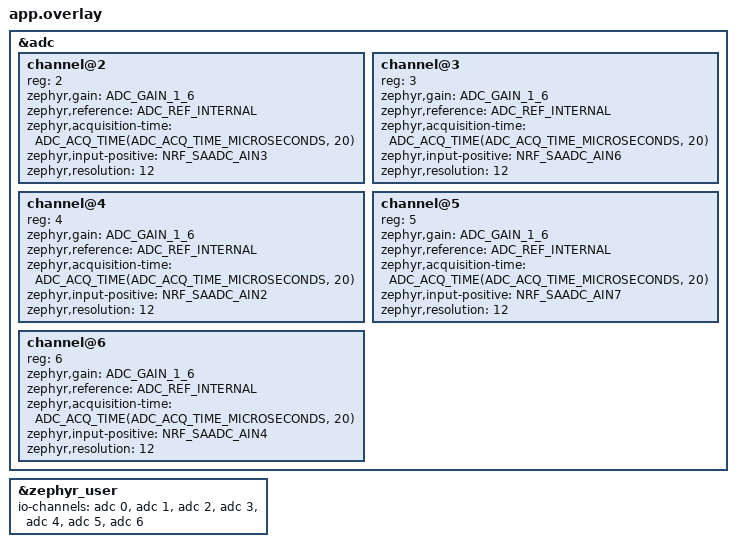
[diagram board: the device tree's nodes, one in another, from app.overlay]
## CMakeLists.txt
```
cmake_minimum_required(VERSION 3.20.0)
find_package(Zephyr REQUIRED HINTS $ENV{ZEPHYR_BASE})
project(sp1-looper)
include(${ZEPHYR_BASE}/samples/subsys/usb/common/common.cmake)
target_sources(app PRIVATE src/main.c src/sp1_emmc.c)

# -fno-strict-aliasing: the firmware type-puns static uint8_t[] storage through
# int16_t* / struct* lvalues (the batchbuf copies and the meta-block cast). This
# removes the TBAA assumption so those puns stay correct under -O2 -- the same
# idiom the Linux kernel and Zephyr core build with. Purely subtractive; it can
# only remove an optimizer assumption, never miscompile correct code.
target_compile_options(app PRIVATE -fno-strict-aliasing)

# NOTE: -O2 on sp1_emmc.c was REVERTED. It sped up reads but BROKE the timing-
# sensitive flash WRITE bit-bang -- ~half of writes failed CRC and retried, which
# overflowed the record ring under record+play load (corruption/glitching). The
# eMMC driver stays at the global -Os, where the write timing is correct.

target_sources_ifdef(CONFIG_SP1_BT_ID_PROBE app PRIVATE src/sp1_bt_probe.c)

# Integration296: maintained source-tree runtime; no build-time source swapping.
set(SP1_BT_DIR ${CMAKE_CURRENT_SOURCE_DIR}/bt)
target_sources(app PRIVATE ${SP1_BT_DIR}/runtime/usb_midi.c)
file(GLOB SP1_SBC_SOURCES ${SP1_BT_DIR}/audio-pipeline/decoder/srce/*.c)
list(FILTER SP1_SBC_SOURCES EXCLUDE REGEX "(synthesis-dct8|decoder-private|synthesis-8-generated).c$")
target_sources(app PRIVATE ${SP1_BT_DIR}/runtime/synthesis-dct8.c ${SP1_BT_DIR}/runtime/decoder-private.c ${SP1_BT_DIR}/runtime/synthesis-8-generated.c ${SP1_SBC_SOURCES} ${SP1_BT_DIR}/runtime/audio_decode.c)
target_include_directories(app PRIVATE ${SP1_BT_DIR}/runtime ${SP1_BT_DIR}/audio-pipeline ${SP1_BT_DIR}/audio-pipeline/decoder/include ${SP1_BT_DIR}/audio-pipeline/decoder/srce)
set_source_files_properties(${SP1_SBC_SOURCES} ${SP1_BT_DIR}/runtime/synthesis-dct8.c ${SP1_BT_DIR}/runtime/decoder-private.c ${SP1_BT_DIR}/runtime/synthesis-8-generated.c PROPERTIES COMPILE_OPTIONS "-fwrapv")
# Candidate344: optimize only SBC decoding and its PCM mix wrapper for speed.
# Keep signed-wrap semantics for codec arithmetic. Never change timing-sensitive
# eMMC/USB/control compilation as a side effect of this experiment.
set_property(SOURCE ${SP1_SBC_SOURCES} ${SP1_BT_DIR}/runtime/synthesis-dct8.c ${SP1_BT_DIR}/runtime/decoder-private.c ${SP1_BT_DIR}/runtime/synthesis-8-generated.c ${SP1_BT_DIR}/runtime/audio_decode.c APPEND PROPERTY COMPILE_OPTIONS -O2)
get_target_property(SP1_CDC_SOURCES subsys__usb__device_next SOURCES)
list(FILTER SP1_CDC_SOURCES EXCLUDE REGEX "usbd_cdc_acm.c$")
set_property(TARGET subsys__usb__device_next PROPERTY SOURCES ${SP1_CDC_SOURCES})
target_sources(subsys__usb__device_next PRIVATE ${SP1_BT_DIR}/runtime/usbd_cdc_acm.c)
target_compile_options(app PRIVATE -fstack-usage)

target_sources(app PRIVATE src/storage373.c)

target_compile_definitions(app PRIVATE FS_FATFS_WINDOW_ALIGNMENT=4)
target_sources(app PRIVATE src/ff.c src/pool.c src/take.c src/session.c src/control.c src/edit.c src/runtime.c src/store_core.c src/admit.c src/backend.c src/audit.c)

target_sources(app PRIVATE src/handoff.c)

target_sources(app PRIVATE src/geometry.c)

target_sources(app PRIVATE src/engine.c src/controls.c src/snapshot.c)

target_sources(app PRIVATE src/cooperative.c)

# Pin414 USB class error-payload fix locally; do not alter the shared SDK.
get_target_property(SP1_UAC_SOURCES subsys__usb__device_next SOURCES)
list(FILTER SP1_UAC_SOURCES EXCLUDE REGEX "usbd_uac2.c$")
set_property(TARGET subsys__usb__device_next PROPERTY SOURCES ${SP1_UAC_SOURCES})
target_sources(subsys__usb__device_next PRIVATE ${SP1_BT_DIR}/runtime/usbd_uac2.c)

# Paged capacity candidate: all metadata buffers overlay the existing batch.
target_sources(app PRIVATE src/paged_bridge.c ../paged/store.c ../paged/catalog.c ../paged/allocate.c ../paged/io.c ../paged/music.c ../paged/session.c ../paged/preview.c)

set(SP1_CAPACITY_BUILD 422 CACHE STRING "Capacity diagnostic identity")
target_compile_definitions(app PRIVATE SP1_CAPACITY_BUILD=${SP1_CAPACITY_BUILD})
```

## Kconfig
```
# SP-1 marisko firmware application Kconfig.
#
# Pulls in the common USB sample options (CONFIG_SAMPLE_USBD_VID/PID/PRODUCT/...)
# consumed by the vendored sample_usbd_init.c device_next bring-up helper, then
# the standard Zephyr Kconfig tree.

source "samples/subsys/usb/common/Kconfig.sample_usbd"

config SP1_BT_ID_PROBE
	bool "Experimental one-shot radio identity probe"
	default n

config SP1_LINK_CALIBRATION
	bool "Stopped-device linked audio calibration experiment"
	depends on SP1_BT_ID_PROBE
	default n

source "Kconfig.zephyr"
```

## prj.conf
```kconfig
CONFIG_PM=y
CONFIG_PM_DEVICE=n
CONFIG_LOG=n
CONFIG_ASSERT=n
CONFIG_USE_SEGGER_RTT=n
CONFIG_IDLE_STACK_SIZE=128
CONFIG_ISR_STACK_SIZE=512
CONFIG_WATCHDOG=y

# ---- FAILSAFES: catch stack overflow / bad memory access cleanly (MPU guard +
# stack canary). Any fatal fault is turned into a reboot by k_sys_fatal_error_handler
# in main.c, and the 4 s watchdog is the final backstop for a hang. ----
# HK-613 (audit §2.5): the MPU stack guard is reprogrammed on every context
# switch (~1 % at the corner). Off; the STACK_SENTINEL canary below, which
# Kconfig had been silently excluding (depends on !MPU_STACK_GUARD), now
# takes effect -- overflow is caught at the next switch/ISR exit, not never.
CONFIG_HW_STACK_PROTECTION=n
CONFIG_STACK_SENTINEL=y
CONFIG_REBOOT=y
CONFIG_CLOCK_CONTROL=y
CONFIG_CLOCK_CONTROL_NRF_K32SRC_SYNTH=y

# ---- USB-serial diagnostics console (CDC ACM) ----
CONFIG_PRINTK=y
CONFIG_SERIAL=y
CONFIG_CONSOLE=y
CONFIG_UART_CONSOLE=y
CONFIG_UART_LINE_CTRL=y
CONFIG_UART_INTERRUPT_DRIVEN=y

# ---- Milestone 3: USB-C audio IN (UAC2) on the new device_next USB stack ----
# UAC2 only exists on the new stack, which is mutually exclusive with the legacy
# CONFIG_USB_DEVICE_STACK. The CDC console therefore moves to device_next too and
# enumerates as a composite (UAC2 speaker + CDC ACM) device.
CONFIG_USB_DEVICE_STACK_NEXT=y
CONFIG_USBD_AUDIO2_CLASS=y
CONFIG_USBD_CDC_ACM_CLASS=y
# SOF events drive the explicit-feedback regulator (sof_cb / feedback_cb).
CONFIG_UDC_ENABLE_SOF=n
# The app owns the single composite USBD context; do NOT let the CDC SYS_INIT
# build a second private context that would fight for the controller.
CONFIG_CDC_ACM_SERIAL_INITIALIZE_AT_BOOT=n
# Serial-number string descriptor.
CONFIG_HWINFO=y
# Composite device identity (replaces the legacy VID/PID/strings). New PID so a
# host does not reuse a cached CDC-only driver from the old firmware.
CONFIG_SAMPLE_USBD_VID=0x1915
CONFIG_SAMPLE_USBD_PID=0x5210
CONFIG_SAMPLE_USBD_MANUFACTURER="softmodded"
CONFIG_SAMPLE_USBD_PRODUCT="SP-1 Audio"
# WINDOWS: usbaudio2.sys demands a 4-byte Full-Speed feedback endpoint (the
# USB spec says 3) and a Q16.16 value — without this the device enumerates
# with a yellow triangle / Code 10 ("cannot start") on Windows. Linux and
# macOS parse the format from the declared size, so this is host-universal.
# (Backported into the Zephyr tree; upstream: USBD_UAC2_FS_WINDOWS_WORKAROUND,
# zephyrproject-rtos/zephyr issue #77212.)
CONFIG_USBD_UAC2_FS_WINDOWS_WORKAROUND=y
# HK-613 (audit §2.5): per-thread cycle accounting cost ~0.5 % per switch and
# only fed the CPU= line; the W4Y census has been the instrument since 473.
CONFIG_THREAD_RUNTIME_STATS=n
CONFIG_SCHED_THREAD_USAGE=n
# iOS: iPhones/iPads reject accessories claiming more than 100 mA over the
# camera adapter. The SP-1 runs from its own battery and barely sips the bus,
# so claim 100 mA (units of 2 mA) instead of the 250 mA default.
CONFIG_SAMPLE_USBD_MAX_POWER=50

# ---- ADC for the button ladders / faders ----
CONFIG_ADC=y

# ---- Milestone 2: I2C to the audio codecs (CS42L42 / TAS2505) ----
CONFIG_I2C=y

# ---- Milestone 2b: I2S audio out (nRF master) ----
CONFIG_I2S=y
CONFIG_I2S_NRFX=y
CONFIG_FPU=y
# NOTE: deliberately NOT setting CONFIG_SPEED_OPTIMIZATIONS=y (-O2). It crashed the
# device on hardware -- this ae5b2e8-derived code has latent signed-overflow UB in
# the mixer interp that -O2 weaponizes. Default -Os is stable. Re-enabling -O2 would
# require fixing that UB (int64 interp) FIRST. Stay on -Os.

# USB stack + printf need a roomier main stack than the bare power build;
# device_next USBD init (descriptor build + class registration) wants headroom.
CONFIG_MAIN_STACK_SIZE=2048

# ---- Always-dim LEDs (fork): the soft-PWM LED timer ISR runs as a ZERO-
# LATENCY interrupt so kernel locks / other IRQs can't delay its on/off edges
# (edge jitter at low duty = visible flicker). The ISR is pure register IO. ----
CONFIG_ZERO_LATENCY_IRQS=y

# SS-473 (probe only -- reverted with prj.conf on exit)
CONFIG_INIT_STACKS=y
CONFIG_THREAD_STACK_INFO=y

CONFIG_COMMON_LIBC_MALLOC_ARENA_SIZE=0
```

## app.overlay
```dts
#include <zephyr/dt-bindings/adc/adc.h>
#include <zephyr/dt-bindings/adc/nrf-saadc.h>
#include <zephyr/dt-bindings/pinctrl/nrf-pinctrl.h>

/* NO MIDI UART: the SP-1 has no MIDI jack. P1.04 (the earlier best-guess MIDI
 * pin) is actually the CYBT-353027 Bluetooth module's UART line per TimK's
 * stemplayer_pins.h — driving it risked contention with the module. The TE
 * firmware's MIDI sync rides the 3.5 mm TRS jack by a path not in the published
 * pinout; revisit only with hardware tracing. */

&adc {
	channel@2 { reg = <2>; zephyr,gain = "ADC_GAIN_1_6"; zephyr,reference = "ADC_REF_INTERNAL";
		zephyr,acquisition-time = <ADC_ACQ_TIME(ADC_ACQ_TIME_MICROSECONDS, 20)>;
		zephyr,input-positive = <NRF_SAADC_AIN3>; zephyr,resolution = <12>; };   /* Fader 1 P0.05 */
	channel@3 { reg = <3>; zephyr,gain = "ADC_GAIN_1_6"; zephyr,reference = "ADC_REF_INTERNAL";
		zephyr,acquisition-time = <ADC_ACQ_TIME(ADC_ACQ_TIME_MICROSECONDS, 20)>;
		zephyr,input-positive = <NRF_SAADC_AIN6>; zephyr,resolution = <12>; };   /* Fader 2 P0.30 */
	channel@4 { reg = <4>; zephyr,gain = "ADC_GAIN_1_6"; zephyr,reference = "ADC_REF_INTERNAL";
		zephyr,acquisition-time = <ADC_ACQ_TIME(ADC_ACQ_TIME_MICROSECONDS, 20)>;
		zephyr,input-positive = <NRF_SAADC_AIN2>; zephyr,resolution = <12>; };   /* Fader 3 P0.04 */
	channel@5 { reg = <5>; zephyr,gain = "ADC_GAIN_1_6"; zephyr,reference = "ADC_REF_INTERNAL";
		zephyr,acquisition-time = <ADC_ACQ_TIME(ADC_ACQ_TIME_MICROSECONDS, 20)>;
		zephyr,input-positive = <NRF_SAADC_AIN7>; zephyr,resolution = <12>; };   /* Fader 4 P0.31 */
	channel@6 { reg = <6>; zephyr,gain = "ADC_GAIN_1_6"; zephyr,reference = "ADC_REF_INTERNAL";
		zephyr,acquisition-time = <ADC_ACQ_TIME(ADC_ACQ_TIME_MICROSECONDS, 20)>;
		zephyr,input-positive = <NRF_SAADC_AIN4>; zephyr,resolution = <12>; };   /* Battery level P0.28 (divider, per SP-1-dev wiki) */
};
&zephyr_user {
	io-channels = <&adc 0>, <&adc 1>, <&adc 2>, <&adc 3>, <&adc 4>, <&adc 5>, <&adc 6>;
};
```

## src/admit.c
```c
#include "admit.h"
#include "store_core.h"
#include <string.h>
typedef struct {FATFS *fs;pool_io io;uint8_t *scratch;uint32_t cached;bool have_cache;} fat_reader;
static uint32_t get32(const uint8_t *p){return p[0]|(uint32_t)p[1]<<8|(uint32_t)p[2]<<16|(uint32_t)p[3]<<24;}
static bool entry(void *ctx,uint32_t cluster,uint32_t *value){
 fat_reader *r=ctx;uint32_t sector=cluster/128,offset=(cluster%128)*4;
 if(cluster>=r->fs->n_fatent||sector>=r->fs->fsize)return false;
 uint64_t a=(uint64_t)r->fs->fatbase+sector,b=a+r->fs->fsize;
 if(b>=r->io.device_blocks)return false;
 if(!r->have_cache||r->cached!=sector){
  if(!r->io.read(r->io.context,(uint32_t)a,r->scratch,1)||
     !r->io.read(r->io.context,(uint32_t)b,r->scratch+512,1))return false;
  r->cached=sector;r->have_cache=true;
 }
 uint32_t first=get32(r->scratch+offset)&0x0fffffff;
 if(first!=(get32(r->scratch+512+offset)&0x0fffffff))return false;
 *value=first;return true;
}
static bool admit(FATFS *fs,pool_io raw,pool_io *out,uint8_t scratch[1024],FIL *file,bool paged){
 if(!fs||!out||!scratch||!file||!raw.read||!raw.write||!raw.sync||fs->fs_type!=FS_FAT32||
    fs->n_fats!=2||fs->n_fatent<65527||!fs->csize||fs->csize>128||
    (fs->csize&(fs->csize-1))||fs->database>=raw.device_blocks)return false;
 uint64_t data_blocks=(uint64_t)(fs->n_fatent-2)*fs->csize;
 if(data_blocks>raw.device_blocks-fs->database)return false;
 sp1_volume data={raw.device_blocks,(uint32_t)fs->database,(uint32_t)data_blocks};
 fat_reader reader={.fs=fs,.io=raw,.scratch=scratch};sp1_extent e[3];
 /* Resolve once during admission, never in the audio/refill path. A present but
  * damaged new namespace must not silently fall back to an old library. */
 const char *names[]={"TAPELOOP/CAT0.BIN","TAPELOOP/CAT1.BIN","TAPELOOP/AUDIO.BIN"};
 FILINFO namespace_info;
 FRESULT ns=f_stat("TAPELOOP",&namespace_info);
 if(ns==FR_NO_FILE||ns==FR_NO_PATH){names[0]="SP1/CAT0.BIN";names[1]="SP1/CAT1.BIN";names[2]="SP1/AUDIO.BIN";}
 else if(ns!=FR_OK||!(namespace_info.fattrib&AM_DIR))return false;
 if(paged){
  if(ns!=FR_OK)return false;
  for(unsigned i=0;i<2;i++){FRESULT old=f_stat(names[i],&namespace_info);if(old!=FR_NO_FILE&&old!=FR_NO_PATH)return false;}
  names[0]="TAPELOOP/INDEX0.BIN";names[1]="TAPELOOP/INDEX1.BIN";
 }
 for(unsigned i=0;i<3;i++){
  if(f_open(file,names[i],FA_READ)!=FR_OK)return false;
  uint64_t bytes=f_size(file);uint32_t cluster=file->obj.sclust;
  bool valid=file->obj.fs==fs&&bytes&&bytes%512==0&&bytes/512<=UINT32_MAX&&
             (i==2?bytes>=16384:bytes==(paged?4194304u:4096u));
  if(f_close(file)!=FR_OK||!valid)return false;
  uint32_t blocks=(uint32_t)(bytes/512),clusters=(blocks+fs->csize-1)/fs->csize;
  if(!sp1_fat_contiguous(data,fs->csize,fs->n_fatent-2,cluster,clusters,entry,&reader,&e[i]))return false;
  /* Catalog files may occupy larger clusters, but the audio pool must consume
   * its whole reservation so allocation cannot expose FAT file slack. */
  if(i==2&&e[i].count!=blocks)return false;
 }
 if(!sp1_extents_disjoint(data,e,3))return false;
 raw.catalog[0]=e[0].first;raw.catalog[1]=e[1].first;raw.pool_first=e[2].first;raw.pool_blocks=e[2].count;
 *out=raw;return true;
}

bool music_fat_admit(FATFS *fs,pool_io raw,pool_io *out,uint8_t scratch[1024]){
 FIL file;return music_fat_admit_workspace(fs,raw,out,scratch,&file);
}

bool music_fat_admit_workspace(FATFS*f,pool_io r,pool_io*out,uint8_t s[1024],FIL*file){return admit(f,r,out,s,file,false);}
bool music_fat_admit_paged(FATFS*f,pool_io r,pool_io*out,uint8_t s[1024],FIL*file){return admit(f,r,out,s,file,true);}
```

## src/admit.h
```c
#ifndef SP1_FAT_ADMIT_H
#define SP1_FAT_ADMIT_H
#include "ff.h"
#include "pool.h"
/* Maintenance-only. Caller owns mounted volume exclusively. This locates and
 * checks the reserved files, both FAT copies and catalog geometry. Unmount and
 * discard FAT caches before handing returned extents to performance mode.
 * Does not format, repair, relocate, validate music or authorize writes. */
bool music_fat_admit(FATFS *,pool_io raw,pool_io *admitted,uint8_t scratch[1024]);
/* Low-stack variant: file object belongs to stopped shared workspace. */
bool music_fat_admit_workspace(FATFS *,pool_io raw,pool_io *admitted,uint8_t scratch[1024],FIL *);
bool music_fat_admit_paged(FATFS *,pool_io,pool_io *,uint8_t[1024],FIL *);
#endif
```

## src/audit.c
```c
#include "stash_ui.h"
#include "backend.h"
#include "paged_bridge.h"
#include "engine.h"
#include "fault.h"
#include "legacy_map.h"
#include "legacy523.h"
#include "sp1_emmc.h"
#include "diskio.h"
#include "storage373.h"
#include <zephyr/sys/printk.h>
#include <zephyr/kernel.h>
#include <string.h>
static music_runtime_retained state;
static uint32_t device_blocks;
static unsigned audit_result;
static write_retry402_trace write402;
extern bool emmc_write_blocks_physical(uint32_t,const uint8_t *,uint32_t);
extern void song373_report(void);
extern void storage415_context_report(uint32_t);
extern void storage418_song_geometry(unsigned,const uint8_t *);
extern void delete435_report(void);
void storage400_report(void){
 delete435_report();
 unsigned f=state.session.writer.fault,reason=(f>>24)&127u,ref=(f>>8)&63u;
 const char *kind=!(f&0x80000000u)?"none":((f>>16)&255u)?"io":reason?"metadata":"transaction";
 printk("FAULT420 class=%s preflight=%u metadata_pending=%u\n",kind,(f&255u)==15,state.session.ownership.writer);

 printk("VALIDATE415 reason=%u song=%u track=%u step=%u io=%u latched=%u\n",reason,reason?ref/4+1:0,reason?ref%4+1:0,f&255u,(f>>16)&255u,(f>>31)&1u);
 if(reason>=64&&reason<=70&&!(f&0x80000000u)){
  const char*why=reason==64?"unavailable":reason==65?"busy":reason==66?"invalid-request":reason==67?"legacy-object-limit":reason==68?"contiguous-audio-reserve":reason==69?"control-reserve":"legacy-take-limit";
  printk("ADMISSION422 refused=%s code=%u fault=0\n",why,reason);
 }
 storage415_context_report(f);
 printk("WRITE412 first_ms=%u recovery_ms=%u\n",write402.first_ms,write402.recovery_ms);
 printk("WRITE406 cleanup=%u stop_probes=%u status_probes=%u r1=%08x\n",write406_trace[0],write406_trace[1],write406_trace[2],write406_trace[3]);
 printk("FAULT400 code=%08x song=%u destination=%u owner=%u writer=%u phase=%u first=%u capacity=%u written=%u generation=%llu active=%u failed=%u\n",state.session.writer.fault,state.session.song,state.session.destination,state.session.ownership.owner,state.session.ownership.writer,state.session.writer_phase,state.session.writer.first,state.session.writer.capacity,state.session.writer.written,(unsigned long long)state.session.writer.generation,state.session.writer.active,state.session.writer.failed);
 printk("WRITE402 first=%08x last=%08x retries=%u recovered=%u exhausted=%u physical=%08x\n",write402.first,write402.last,write402.retries,write402.recovered,write402.exhausted,emmc_write_failure402);
}
bool storage400_fault(void){return music_fault_pending(&state);}
void storage400_failed(void){music_fault_fail(&state,0);state.session.ownership.owner=SP1_STORE_INVALID;}
extern void switch439_report(void);
void storage373_report(void){switch439_report();song373_report();storage400_report();printk("MAP373 song=%u owner=%u writer=%u phase=%u\n",state.session.song,state.session.ownership.owner,state.session.ownership.writer,state.session.writer_phase);printk("STORAGE373 RESULT format=%u blocks=%u\n",audit_result,device_blocks);printk("CAPACITY422 backend=%s\n",music_backend_paged()?"paged":storage523_legacy()?"legacy":"fixed");printk("SETUP539 CAPS radio_direct=1\n");printk("READY427 prepared=%u audition=%u\n",state.session.writer_phase==MUSIC_PREPARED427,state.session.writer_phase==MUSIC_AUDITION427);}
bool storage373_pool(void){return audit_result==MUSIC_MEDIA_POOL;}
bool storage523_legacy(void){return audit_result==MUSIC_MEDIA_LEGACY;}
void storage523_report(void){printk("BASIC523 CAPS legacy=%u takes=%u drive=%u\n",storage523_legacy(),storage373_pool(),storage373_pool());}
#include "cooperative.h"
static bool scheduled;
void storage373_scheduling(bool on){scheduled=on;}
extern bool storage373_service(void),storage373_live(void);
extern int emmc_commit_flush_step(void);
static bool service(void *c){(void)c;bool ok=storage373_service();if(!ok)music_fault_fail(&state,4);return ok;}
static bool raw_rd(void *c,uint32_t b,void *p,uint32_t n){(void)c;return emmc_read_blocks(b,p,n);}
static bool raw_wr(void *c,uint32_t b,const void *p,uint32_t n){(void)c;return emmc_write_blocks_physical(b,p,n);}
static bool retry_wr(void *c,uint32_t b,const void *p,uint32_t n,uint32_t ms){(void)c;return emmc_write_blocks_retry402(b,p,n,ms);}
static uint32_t write_now(void *c){(void)c;return k_uptime_get_32();}
static uint32_t write_reason(void *c){(void)c;return emmc_write_failure402;}
static bool private_raw_wr(void *c,uint32_t b,const void *p,uint32_t n){
 const write_retry402_io io={c,raw_wr,retry_wr,write_now,write_reason};
 return write_retry402(&io,&write402,b,p,n);
}
static int flush_step(void *c){(void)c;int result=storage373_live()?emmc_commit_flush_step():(emmc_cache_flush()?1:-1);if(result<0)music_fault_fail(&state,5);return result;}
/*421: catalog publication writes only the inactive checkpoint. Replay the
 * identical bounded sector span, never restart the transaction or advance its
 * generation twice. The driver must re-establish READY/TRANSFER first.
 * persist() still flushes then verifies all encoded checkpoint bytes. */
static bool commit_raw_wr(void *c,uint32_t b,const void *p,uint32_t n){
 if(n<2)return raw_wr(c,b,p,n); /* single-sector errors remain fail-closed */
 return private_raw_wr(c,b,p,n);
}
static const cooperative_io coop={NULL,service,raw_rd,commit_raw_wr,flush_step};
static const cooperative_io private_coop={NULL,service,raw_rd,private_raw_wr,flush_step};
static bool rd(void *c,uint32_t b,void *p,uint32_t n){bool ok=scheduled?cooperative_read(&coop,b,p,n):raw_rd(c,b,p,n);if(!ok)music_fault_fail(&state,1);return ok;}
static bool wr(void *c,uint32_t b,const void *p,uint32_t n){bool ok=scheduled?cooperative_write(&coop,b,p,n):commit_raw_wr(c,b,p,n);if(!ok)music_fault_fail(&state,2);return ok;}
static bool private_wr(void *c,uint32_t b,const void *p,uint32_t n){bool ok=scheduled?cooperative_write(&private_coop,b,p,n):private_raw_wr(c,b,p,n);if(!ok)music_fault_fail(&state,2);return ok;}
static bool sync_io(void *c){(void)c;bool ok=scheduled?cooperative_flush(&coop):emmc_cache_flush();if(!ok)music_fault_fail(&state,3);return ok;}
DSTATUS disk_initialize(BYTE drive){return drive?STA_NOINIT:0;}
DSTATUS disk_status(BYTE drive){return drive?STA_NOINIT:0;}
DRESULT disk_read(BYTE drive,BYTE *p,LBA_t b,UINT n){if(drive||!n||b>=device_blocks||n>device_blocks-b)return RES_PARERR;return rd(NULL,b,p,n)?RES_OK:RES_ERROR;}
DRESULT disk_ioctl(BYTE drive,BYTE cmd,void *p){if(drive)return RES_PARERR;switch(cmd){case CTRL_SYNC:return RES_OK;case GET_SECTOR_COUNT:*(LBA_t*)p=device_blocks;return RES_OK;case GET_SECTOR_SIZE:*(WORD*)p=512;return RES_OK;case GET_BLOCK_SIZE:*(DWORD*)p=1;return RES_OK;default:return RES_PARERR;}}
void storage373_audit(music_runtime_workspace *w){
 music_session_init(&state.session);uint8_t *p=w->streaming_batch;
 if(!emmc_read_ext_csd(p))return;
 device_blocks=(uint32_t)p[212]|(uint32_t)p[213]<<8|(uint32_t)p[214]<<16|(uint32_t)p[215]<<24;
 pool_io raw={.read=rd,.write=wr,.sync=sync_io,.device_blocks=device_blocks};
 audit_result=music_backend_mount(&state,w,raw,true);
 if(!storage373_pool()){music_session_init(&state.session);state.session.ownership.owner=SP1_STORE_INVALID;}
 printk("STORAGE373 AUDIT format=%u blocks=%u\n",audit_result,device_blocks);
}
bool storage373_read_controls(music_runtime_workspace *w,uint32_t b,uint8_t *p,uint32_t n){
 if(!storage373_pool())return emmc_read_blocks(b,p,n);
 if(!n||b>=6||n>6-b||!music_backend_controls(&state,w,w->stopped_song.controls,true))return false;
 memmove(p,w->stopped_song.controls+b*512,n*512);return true;
}
bool storage373_song(unsigned song,uint32_t first,uint32_t stride,music_runtime_workspace *w){
 if(!storage373_pool())return legacy_map_bind(&state.session,audit_result==MUSIC_MEDIA_LEGACY,song,device_blocks,first,stride);
 bool ok=music_engine_load(&state,w,song,true);
 if(ok)storage418_song_geometry(song,w->stopped_song.controls);
 return ok;
}
bool storage373_map(uint32_t b,uint32_t n,uint32_t first,uint32_t stride,uint32_t *physical){return legacy_map_read(&state.session,b,n,first,stride,physical);}
/* Legacy address writes are never allowed onto FAT media. Pool transactions
 * alone call the physical primitive, after bounded admission/reservation. */
bool emmc_write_blocks(uint32_t b,const uint8_t *p,uint32_t n){return storage523_legacy()&&legacy523_write_range(b,n,device_blocks)&&private_raw_wr(NULL,b,p,n);}
static bool snap(void *ctx,unsigned n,uint8_t out[512]){if(n>=6)return false;memmove(out,(uint8_t*)ctx+n*512,512);return true;}
bool storage373_save(music_runtime_workspace *w){return music_engine_save(&state,w,snap,w->stopped_song.controls,true);}
bool storage401_prepare(music_runtime_workspace *w,unsigned track,uint32_t capacity,bool fresh_replace){
 if(!w||track>=4||storage400_fault())return false;
 if(state.session.ownership.writer)return state.session.destination==state.session.song*4+track;
 if(music_backend_paged()&&music_prepared427_claim(&state.session,track,capacity))return true;
 music_fault_step(&state,MUSIC_PREP_LOAD);
 if(!music_engine_load(&state,w,state.session.song,true))return false;
 /*426: this freshly validated snapshot already belongs to this operation.
  * Do not reload it twice again before reserving the empty recording. */
 if(music_backend_paged())return bridge426_prepare_loaded(&state,w,track,capacity,!fresh_replace&&w->stopped_song.loaded[track].audio_blocks!=0);
 if(!w->stopped_song.loaded[track].audio_blocks)return music_engine_begin(&state,w,track,capacity,false,true);
 return fresh_replace?music_engine_prepare_replace(&state,w,track,capacity,true):music_engine_prepare_edit(&state,w,track,capacity,true);
}
bool storage373_prepare(music_runtime_workspace *w,unsigned track,uint32_t capacity){return storage401_prepare(w,track,capacity,false);}
bool storage373_prepare_step(music_runtime_workspace *w){
 if(storage400_fault())return false;
 if(state.session.writer_phase!=1)return state.session.writer_phase==2;
 if(state.session.writer.written<state.session.tracks[state.session.destination%4].count+TAKE_HEADER_BLOCKS){
  music_fault_step(&state,MUSIC_PREP_COPY);
  return music_session_edit_step(&state.session,state.io,w->streaming_batch,8);
 }
 music_fault_step(&state,MUSIC_PREP_VERIFY);
 if(music_backend_paged())return bridge422_ready(&state,w);
 return music_session_edit_ready(&state.session,&w->stopped_song.pool,state.io);
}
bool storage373_record_ready(unsigned track){return __atomic_load_n(&state.session.writer_phase,__ATOMIC_ACQUIRE)==2&&state.session.destination==state.session.song*4+track;}
bool storage373_writer(void){return state.session.ownership.writer;}
bool storage373_abort(void){return !storage400_fault()&&music_session_abort(&state.session,true);}
uint32_t storage373_written(void){return state.session.writer.written>=TAKE_HEADER_BLOCKS?state.session.writer.written-TAKE_HEADER_BLOCKS:0;}
bool storage373_write(unsigned track,uint32_t offset,const uint8_t *p,uint32_t n,uint8_t scratch[512]){
 pool_io private_io=state.io;private_io.write=private_wr;
 return state.session.destination==state.session.song*4+track&&music_session_write(&state.session,private_io,offset,p,n,scratch);
}
bool storage373_finish(music_runtime_workspace *w,const take_metadata *m){return music_engine_finish_snapshot(&state,w,m,snap,w->stopped_song.controls,true);}
bool storage373_action(music_runtime_workspace *w,unsigned action,unsigned track,unsigned slot){
 if(!storage373_pool()||storage373_writer()||track>=4||slot>=64)return false;
 if(action==22)return music_engine_stash(&state,w,track,slot,true);
 if(action==23)return music_engine_recall(&state,w,slot,track,true);
 if(action==24)return music_engine_drop(&state,w,64+slot,true);
 return false;
}
extern bool emmc_write_blocks_async_physical(uint32_t,const uint8_t *,uint32_t);
bool emmc_write_blocks_async(uint32_t b,const uint8_t *p,uint32_t n){return storage523_legacy()&&legacy523_write_range(b,n,device_blocks)&&emmc_write_blocks_async_physical(b,p,n);}

bool storage381_valid(void){return state.session.ownership.owner!=SP1_STORE_INVALID;}
/* Storage-thread only, existing workspace; no cached catalog or audio buffer. */
int storage384_choose(music_runtime_workspace *w,unsigned track,unsigned action,unsigned requested){
 if(track>=4||!storage373_pool()||storage373_writer()||!music_engine_load(&state,w,state.session.song,true))return -1;
 if(music_backend_paged())return -1; /* retired64-slot protocol */
 pool_store *p=&w->stopped_song.pool;unsigned lane=state.session.song*4+track;int slot=-1;
 if(action==3){for(unsigned i=0;i<64;i++)if(p->current.ref[64+i]==SP1_POOL_NONE)return i;return -1;}
 if(action==4)return pool_lane_selected(&p->current,lane);
 if(action==6){
  if(requested>=64||p->current.ref[64+requested]==SP1_POOL_NONE||p->current.lane[requested])return -1;
  if(!pool_lane_claim(p,lane,requested)||!pool_lane_commit(p))return -1;return requested;
 }
 slot=action==5?(int)requested:pool_lane_browse(&p->current,lane,action==1?-1:1);
 if(slot<0||!pool_lane_select(p,lane,slot)||!pool_lane_commit(p))return -1;
 return slot;
}

#include "takes.h"
int storage397_cycle(music_runtime_workspace *w,unsigned track,int direction,unsigned *ordinal){
 if(!storage373_pool()||storage373_writer())return -1;
 return music_engine_cycle(&state,w,track,direction,ordinal);
}
bool storage397_publish(music_runtime_workspace *w,unsigned track){
 if(track>=4||!storage373_pool()||storage373_writer())return false;
 if(music_backend_paged())return bridge422_publish(&state,w,track);
 pool_store *p=&w->stopped_song.pool;unsigned ref=state.session.song*4+track,id=p->current.ref[ref];
 sp1_extent next={0};
 if(id!=SP1_POOL_NONE){
  if(id>=SP1_POOL_OBJECTS||p->current.object[id].blocks<TAKE_HEADER_BLOCKS)return false;
  next=(sp1_extent){state.io.pool_first+p->current.object[id].first+TAKE_HEADER_BLOCKS,w->stopped_song.loaded[track].audio_blocks};
 }
 /* Target is drained. No reads/writes between mapping publication and the
  * audio-boundary control handoff; peer maps and rings remain untouched. */
 state.session.tracks[track]=next;return true;
}

void storage420_reject(unsigned track,unsigned reason){
 music_fault_step(&state,14);music_fault_context(&state,state.session.song*4+track,reason);music_fault_fail(&state,0);
}

bool storage420_preflight(music_runtime_workspace *w){return music_engine_preflight(&state,w,true);}

void storage427_warm(music_runtime_workspace*w,uint32_t capacity){
 if(music_backend_paged()&&!storage400_fault()&&!state.session.writer_phase)
  (void)bridge427_warm(&state,w,capacity);
}
bool storage427_audition(unsigned track,const take_metadata*m){
 return music_backend_paged()&&!storage400_fault()&&music_audition427(&state.session,state.io,track,m);
}

#include "predict437.h"
int storage437_predict(music_runtime_workspace*w,unsigned track,int direction,switch437_ticket*t){
 if(!music_backend_paged()||!storage373_pool()||storage373_writer())return -2;
 return bridge437_predict(&state,w,track,direction,t);
}
extern void music_engine_refresh437(music_runtime_retained*,music_runtime_workspace*);
bool storage437_finish(music_runtime_workspace*w,const switch437_ticket*t){bool ok=bridge437_finish(&state,w,t);if(ok)music_engine_refresh437(&state,w);return ok;}

bool storage440_extend(music_runtime_workspace*w,switch437_ticket*t,uint32_t actions,unsigned count){return bridge440_extend(&state,w,t,actions,count);}
```

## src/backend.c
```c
#include "backend.h"
#include <string.h>
#include "paged_bridge.h"
#include "legacy523.h"
static bool paged_media;
bool music_backend_paged(void){return paged_media;}
static void reject(music_runtime_retained *r){
 music_session_init(&r->session);r->session.ownership.owner=SP1_STORE_INVALID;
 memset(&r->io,0,sizeof(r->io));
}
static bool borrowable(const music_runtime_retained *r,bool stopped){
 return r&&stopped&&!r->session.ownership.readers&&!r->session.ownership.writer&&
  (r->session.ownership.owner==SP1_STORE_VALIDATING||r->session.ownership.owner==SP1_STORE_PERFORMANCE);
}
music_media music_backend_mount(music_runtime_retained *r,music_runtime_workspace *w,pool_io raw,bool stopped){
 if(!borrowable(r,stopped)||!w||!raw.read||!raw.write||!raw.sync||!raw.device_blocks)return MUSIC_MEDIA_INVALID;
 /* Reject the old map immediately, even if remount later fails. */
 reject(r);paged_media=false;
 uint8_t *p=w->streaming_batch;
 if(!raw.read(raw.context,0,p,2))return MUSIC_MEDIA_INVALID;
 if(p[0]==0x41&&p[1]==0x33&&p[2]==0x45&&p[3]==0x53){
  if(!raw.read(raw.context,0,p,6)||!legacy523_valid(p,3072,raw.device_blocks))return MUSIC_MEDIA_INVALID;
  return MUSIC_MEDIA_LEGACY;
 }
 /* diskio callbacks must use raw I/O, never the mapped playback API. */
 memset(&w->mount,0,sizeof(w->mount));
 FRESULT mounted=f_mount(&w->mount.fs,"",1);
 FILINFO info;FRESULT a=mounted==FR_OK?f_stat("TAPELOOP/INDEX0.BIN",&info):FR_DISK_ERR,b=mounted==FR_OK?f_stat("TAPELOOP/INDEX1.BIN",&info):FR_DISK_ERR;
 bool paged=a==FR_OK||b==FR_OK;
 bool names_ok=(a==FR_OK||a==FR_NO_FILE||a==FR_NO_PATH)&&(b==FR_OK||b==FR_NO_FILE||b==FR_NO_PATH);
 bool admitted=mounted==FR_OK&&names_ok&&(paged?music_fat_admit_paged:music_fat_admit_workspace)(&w->mount.fs,raw,&r->io,w->mount.scratch,&w->mount.file);
 /* FatFs registers the object even on failed mount: always detach it before
  * returning the shared workspace to catalog or streaming use. */
 bool detached=f_mount(NULL,"",0)==FR_OK;
 if(!admitted||!detached){reject(r);return MUSIC_MEDIA_INVALID;}
 if(paged){
  paged_media=true;cat422_workspace*pw=(void*)w;
  if(!bridge422_open(r,w)||!cat422_controls_load(pw,&pw->device)){paged_media=false;reject(r);return MUSIC_MEDIA_INVALID;}
  music_session_init(&r->session);return MUSIC_MEDIA_POOL;
 }
 if(!pool_open(&w->stopped_song.pool,r->io)||!music_control_verify(&w->stopped_song.pool)){
  reject(r);return MUSIC_MEDIA_INVALID;
 }
 music_session_init(&r->session);return MUSIC_MEDIA_POOL;
}
bool music_backend_controls(music_runtime_retained *r,music_runtime_workspace *w,uint8_t out[3072],bool stopped){
 if(!borrowable(r,stopped)||!w||!out||!r->io.read)return false;
 if(paged_media){cat422_workspace*p=(void*)w;if(!bridge422_open(r,w)||!cat422_controls_load(p,&p->device)){reject(r);return false;}memmove(out,p->controls,3072);return true;}
 pool_store *s=&w->stopped_song.pool;
 if(!pool_open(s,r->io)||!music_control_load(s,out)){reject(r);return false;}
 return true;
}
bool music_backend_song(music_runtime_retained *r,music_runtime_workspace *w,unsigned song,bool stopped){
 if(!borrowable(r,stopped)||!w||!r->io.read||song>=16)return false;
 if(paged_media)return bridge422_load(r,w,song);
 return music_session_load(&r->session,&w->stopped_song.pool,r->io,song,w->stopped_song.loaded);
}
bool music_backend_load(music_runtime_retained *r,music_runtime_workspace *w,unsigned song,bool stopped){
 if(!borrowable(r,stopped)||!w||!r->io.read||song>=16)return false;
 if(paged_media)return bridge422_load(r,w,song);
 pool_store *s=&w->stopped_song.pool;
 if(!pool_open(s,r->io)||!music_control_load(s,w->stopped_song.controls)){
  /* Runtime reload must retain the first I/O fault and the last writer's
   * reservation evidence. Full reject/reset is for mount admission only. */
  memset(r->session.tracks,0,sizeof(r->session.tracks));
  r->session.ownership.owner=SP1_STORE_INVALID;return false;
 }
 return music_session_load_opened(&r->session,s,song,w->stopped_song.loaded);
}
```

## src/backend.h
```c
#ifndef SP1_RUNTIME_BACKEND_H
#define SP1_RUNTIME_BACKEND_H
#include "music_workspace.h"
#include "admit.h"
typedef enum { MUSIC_MEDIA_INVALID, MUSIC_MEDIA_LEGACY, MUSIC_MEDIA_POOL } music_media;
/* Storage-thread-only mount. Caller supplies exclusive raw I/O and the existing
 * stopped batch workspace. No format/repair/write is attempted. Legacy detection
 * never authorizes pool operations; caller keeps its existing legacy backend.
 * Mounted FAT state never survives this call. */
music_media music_backend_mount(music_runtime_retained *,music_runtime_workspace *,pool_io raw,bool stopped_drained);
/* Read controls once while validating their complete CRC.
 * Caller applies only after all metadata and song load have succeeded, before
 * resuming audio. Output is caller's existing six-sector metadata buffers. */
bool music_backend_controls(music_runtime_retained *,music_runtime_workspace *,uint8_t out[3072],bool stopped_drained);
bool music_backend_song(music_runtime_retained *,music_runtime_workspace *,unsigned song,bool stopped_drained);
/* One serialized catalog open for controls plus selected-song metadata. No
 * pointers into this workspace survive the call. Caller still cross-checks
 * song geometry before applying controls or permitting playback. */
bool music_backend_load(music_runtime_retained *,music_runtime_workspace *,unsigned song,bool stopped_drained);
#endif
```

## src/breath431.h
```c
#ifndef BREATH431_H
#define BREATH431_H
#include <stdint.h>
/*435: 3.2 seconds fully dark, 0.8s fade up, 0.8s fade down.
 * Smoothstep lookup in flash; integer interpolation only at LED cadence. */
static unsigned breath431_level(uint32_t ms){
 static const uint8_t ease[17]={0,2,8,18,30,44,61,78,96,114,131,148,162,174,184,190,192};
 unsigned p=ms%4800u;if(p<3200u)return 0;
 p-=3200u;if(p>800u)p=1600u-p;
 unsigned i=p/50u,f=p%50u;if(i>=16)return 192;
 return ease[i]+(ease[i+1]-ease[i])*f/50u;
}
#endif
```

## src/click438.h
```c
#ifndef CLICK438_H
#define CLICK438_H
#include <stdint.h>
/* One word: eight ordered 2-bit actions, count4, candidate2, stable2,
 * latched1, cancelled1. Owner/lane lives in the active request. Call under
 * the existing short IRQ lock; never scan ADC or do I/O under that lock. */
#define CLICK438_SAMPLES 2u
#define CLICK438_LATCH (1u<<24)
#define CLICK438_CANCEL (1u<<25)
static inline uint32_t click438_start(void){return CLICK438_LATCH;}
static inline uint32_t click438_sample(uint32_t s,int held,unsigned op){
 if(!held)return CLICK438_CANCEL;
 if(s&CLICK438_CANCEL)return s;
 unsigned c=(s>>20)&3u,n=(s>>22)&3u;
 if(op>2)op=3; /* unrelated rocker/volume is inert, never a neutral */
 if(c!=op){c=op;n=1;}else if(n<3)n++;
 s=(s&~(15u<<20))|(c<<20)|(n<<22);
 if(n<CLICK438_SAMPLES)return s;
 if(!op)return s&~CLICK438_LATCH;
 if(op==3||s&CLICK438_LATCH)return s;
 s|=CLICK438_LATCH;unsigned count=(s>>16)&15u;
 if(count<8){s|=op<<(count*2);s=(s&~(15u<<16))|((count+1)<<16);}
 return s;
}
static inline unsigned click438_pop(uint32_t *s){
 unsigned n=(*s>>16)&15u;if((*s&CLICK438_CANCEL)||!n){*s=0;return 0;}
 unsigned op=*s&3u;*s=(*s&~0xfffffu)|((*s&65535u)>>2)|((n-1)<<16);return op;
}
/* Drain pending actions as one ordered burst while retaining edge debounce.
 * Cancellation remains latched until the owner request finishes. */
static inline unsigned click440_batch(uint32_t *s,uint32_t *actions){
 if(*s&CLICK438_CANCEL){*actions=0;return 0;}
 unsigned count=(*s>>16)&15u;*actions=*s&65535u;*s&=~0xfffffu;return count;
}
#endif
```

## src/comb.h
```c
#ifndef SP1_COMB387_H
#define SP1_COMB387_H
#include <stdint.h>
#include <stdbool.h>
#include <string.h>
#define COMB_N 512u
/* Controls survive engine switches; DSP history shares reverb's allocation. */
typedef struct {uint8_t level[4],tune[4],decay[4],damp[4],mix;} comb_controls;
#define COMB_DEFAULT { {0,0,0,0},{64,85,101,128},{160,160,160,160},{160,160,160,160},128 }
typedef struct {
 int16_t line[4][COMB_N],fir[64];
 int32_t lp[4],delay[4],level[4],feedback[4],alpha[4];
 int32_t excitation[64],wet[2][64];
 int32_t hp,prev,mix;
 int32_t delta[4][5],goal[4][5],mix_delta,mix_goal;
 uint32_t w,fw,blocks,max_us,clips;
} comb_state;
_Static_assert(sizeof(comb_state)<=8192,"comb fits reverb allocation");
#include "comb_tables.h"
static inline int32_t comb_sat(int32_t x){return x>32767?32767:x< -32768?-32768:x;}
static inline int32_t comb_slew(int32_t x,int32_t t){int32_t d=t-x;return x+(d>0?(d+63)/64:d<0?(d-63)/64:0);}
static inline unsigned comb_pitch_index(uint8_t q,bool snap){return snap?256u+((unsigned)q*48u+127u)/255u:q;}
static inline void comb_targets(const comb_controls *c,bool snap,int32_t delay[4],int32_t fb[4],int32_t alpha[4]){
 for(unsigned v=0;v<4;v++){unsigned d=c->damp[v]>>4;delay[v]=comb_delays[d][comb_pitch_index(c->tune[v],snap)];fb[v]=24576+((int32_t)c->decay[v]*8028)/255;alpha[v]=comb_alpha[d];}
}
static inline void comb_begin(comb_state *s,const comb_controls *c,bool snap){
 int32_t td[4],tf[4],ta[4];comb_targets(c,snap,td,tf,ta);
 for(unsigned v=0;v<4;v++){
  if(!s->delay[v])s->delay[v]=td[v];
  int32_t now[5]={s->delay[v],s->level[v],s->feedback[v],s->alpha[v],0};
  int32_t to[5]={s->delay[v]+(td[v]-s->delay[v])/4,(int32_t)c->level[v]*128,s->feedback[v]+(tf[v]-s->feedback[v])/4,s->alpha[v]+(ta[v]-s->alpha[v])/4,0};
  for(unsigned j=0;j<4;j++){s->goal[v][j]=to[j];s->delta[v][j]=(to[j]-now[j])/64;}
 }
 s->mix_goal=(int32_t)c->mix*128;s->mix_delta=(s->mix_goal-s->mix)/64;
}
static inline void comb_end(comb_state *s){
 for(unsigned v=0;v<4;v++){s->delay[v]=s->goal[v][0];s->level[v]=s->goal[v][1];s->feedback[v]=s->goal[v][2];s->alpha[v]=s->goal[v][3];}s->mix=s->mix_goal;
}
/* Mirrored FIR history makes each32-tap dot product contiguous. ARM uses
 * signed dual16-bit MAC; portable branch exercises the same integer result. */
static inline int32_t comb_input(comb_state *s,const int32_t *l,const int32_t *r){
 for(unsigned j=0;j<4;j++){int16_t x=comb_sat((l[j]/2)+(r[j]/2));s->fir[s->fw]=x;s->fir[s->fw+32]=x;s->fw=(s->fw+1)&31u;}
 int32_t a=0;
 for(unsigned j=0;j<32;j+=2){
#if defined(__arm__) && defined(__ARM_FEATURE_DSP)
  uint32_t x,h;memcpy(&x,s->fir+s->fw+j,4);memcpy(&h,comb_fir+j,4);
  __asm__("smlad %0, %1, %2, %0" : "+r"(a) : "r"(x), "r"(h));
#else
  a+=(int32_t)s->fir[s->fw+j]*comb_fir[j]+(int32_t)s->fir[s->fw+j+1]*comb_fir[j+1];
#endif
 }
 int32_t x=a>>15;s->hp=comb_sat(x-s->prev+((s->hp*32604)>>15));s->prev=x;return s->hp>>3;
}
static inline void comb_step(comb_state *s,int32_t in,int32_t *left,int32_t *right){
 static const uint16_t pan[4]={224,160,96,32};int32_t l=0,r=0;
 for(unsigned v=0;v<4;v++){
  s->delay[v]+=s->delta[v][0];s->level[v]+=s->delta[v][1];s->feedback[v]+=s->delta[v][2];s->alpha[v]+=s->delta[v][3];
  uint32_t d=(uint32_t)s->delay[v],n=d>>12,f=d&4095u;
  int32_t a=s->line[v][(s->w-n)&511u],b=s->line[v][(s->w-n-1)&511u];
  int32_t y=a+(((b-a)*(int32_t)f)>>12);
  s->lp[v]+=(((y-s->lp[v])*s->alpha[v])>>15);
  int32_t z=in+((s->lp[v]*s->feedback[v])>>15);
  if(z>32767||z< -32768)s->clips++;
  s->line[v][s->w]=comb_sat(z);
  int32_t wet=((y*s->level[v])>>15);
  l+=((wet*pan[v])>>8);r+=((wet*(256-pan[v]))>>8);
 }
 s->w=(s->w+1)&511u;s->mix+=s->mix_delta;
 *left=((l*s->mix)>>16);*right=((r*s->mix)>>16);
}

/* Effect-major bank: input filtering once, each voice in a compact loop,
 * output interpolation once. Scratch lives inside the reverb union. */
static __attribute__((optimize("O3"),noinline)) void comb_render(comb_state *s,int32_t *l,int32_t *r,int32_t *prevL,int32_t *prevR){
 for(unsigned k=0;k<64;k++){s->excitation[k]=comb_input(s,l+4*k,r+4*k);s->wet[0][k]=s->wet[1][k]=0;}
 static const int32_t pans[4]={224,160,96,32};
 for(unsigned v=0;v<4;v++){
  int32_t delay=s->delay[v],level=s->level[v],fb=s->feedback[v],alpha=s->alpha[v],lp=s->lp[v];
  for(unsigned k=0;k<64;k++){
   delay+=s->delta[v][0];level+=s->delta[v][1];fb+=s->delta[v][2];alpha+=s->delta[v][3];
   unsigned w=(s->w+k)&511u,n=(unsigned)delay>>12,f=(unsigned)delay&4095u;
   int32_t a=s->line[v][(w-n)&511u],b=s->line[v][(w-n-1)&511u];
   int32_t y=a+(((b-a)*(int32_t)f)>>12);lp+=((y-lp)*alpha)>>15;
   int32_t z=s->excitation[k]+((lp*fb)>>15);if(z>32767||z< -32768)s->clips++;
   s->line[v][w]=comb_sat(z);int32_t wet=(y*level)>>15;
   s->wet[0][k]+=(wet*pans[v])>>8;s->wet[1][k]+=(wet*(256-pans[v]))>>8;
  }s->lp[v]=lp;
 }
 int32_t pl=*prevL,pr=*prevR,mix=s->mix;
 for(unsigned k=0;k<64;k++){
  mix+=s->mix_delta;int32_t ol=(s->wet[0][k]*mix)>>16,orr=(s->wet[1][k]*mix)>>16;
  for(unsigned j=0;j<4;j++){l[k*4+j]+=pl+(ol-pl)*(int32_t)j/4;r[k*4+j]+=pr+(orr-pr)*(int32_t)j/4;}
  pl=ol;pr=orr;
 }s->w=(s->w+64u)&511u;*prevL=pl;*prevR=pr;comb_end(s);
}
#endif
```

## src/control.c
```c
#include "control.h"
bool music_control_save(pool_store *s,music_control_snapshot snapshot,void *ctx){
 if(!s||!s->ready||!snapshot)return false;
 pool_writer writer;if(!pool_prepare_writer(s,MUSIC_CONTROL_BLOCKS,&writer)){s->ready=false;return false;}
 for(unsigned i=0;i<MUSIC_CONTROL_BLOCKS;i++){
  if(!snapshot(ctx,i,s->bytes)||!pool_writer_append(s->io,&writer,s->bytes,1)){s->ready=false;return false;}
 }
 return pool_finish_control(s,&writer,MUSIC_CONTROL_TAG);
}
bool music_control_read(pool_store *s,unsigned sector,uint8_t out[512]){
 if(!s||!s->ready||!s->current.control||sector>=MUSIC_CONTROL_BLOCKS)return false;
 pool_object o=s->current.object[s->current.control-1];
 return o.tag==MUSIC_CONTROL_TAG&&o.blocks==MUSIC_CONTROL_BLOCKS&&pool_read_control(s,sector,out,1);
}
bool music_control_verify(pool_store *s){
 if(!s)return false;
 uint32_t crc=UINT32_MAX;
 for(unsigned i=0;i<MUSIC_CONTROL_BLOCKS;i++){
  if(!music_control_read(s,i,s->bytes))return false;
  crc=pool_crc(crc,s->bytes,512);
 }
 return ~crc==s->current.object[s->current.control-1].crc;
}
bool music_control_load(pool_store *s,uint8_t out[MUSIC_CONTROL_BLOCKS*512]){
 if(!s||!out)return false;
 uint32_t crc=UINT32_MAX;
 for(unsigned i=0;i<MUSIC_CONTROL_BLOCKS;i++){
  uint8_t *sector=out+i*512;
  if(!music_control_read(s,i,sector))return false;
  crc=pool_crc(crc,sector,512);
 }
 return ~crc==s->current.object[s->current.control-1].crc;
}
```

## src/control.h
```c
#ifndef SP1_MUSIC_CONTROL_H
#define SP1_MUSIC_CONTROL_H
#include "pool.h"
#define MUSIC_CONTROL_TAG 0x314c5443u
#define MUSIC_CONTROL_BLOCKS 6u
/* Exact maintained looper metadata sectors0..5. Native encoding remains
 * versioned by its existing magic/checksums. Caller validates semantics before
 * applying. Controls and take references publish in a single catalog commit.
 * Snapshot callback must be stable for all six calls (storage-thread barrier). */
typedef bool (*music_control_snapshot)(void *,unsigned sector,uint8_t out[512]);
bool music_control_save(pool_store *,music_control_snapshot,void *);
bool music_control_read(pool_store *,unsigned sector,uint8_t out[512]);
bool music_control_verify(pool_store *);
/* Read and verify once into the caller's existing six-sector buffer. The output
 * is private/unusable unless this returns true; semantic checks still follow.
 * The opened catalog and output must remain exclusively owned for this call. */
bool music_control_load(pool_store *,uint8_t out[MUSIC_CONTROL_BLOCKS*512]);
#endif
```
